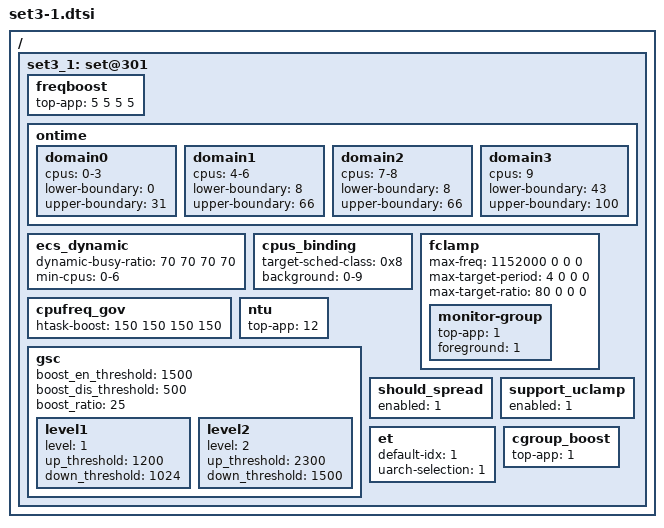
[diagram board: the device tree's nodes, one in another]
/ {
	/* game mode - boost app*/
	set3_1: set@301{
		/* Boosting margin applied to frequency selection */
		freqboost {			/* LIT MED-L MED-H BIG */
			top-app			= < 5  5  5  5 >;
		};

		/* Ontime Migration */
		ontime {
			domain0 {
				cpus = "0-3";
				lower-boundary = <0>;
				upper-boundary = <31>;
			};
			domain1 {
				cpus = "4-6";
				lower-boundary = <8>;
				upper-boundary = <66>;
			};
			domain2 {
				cpus = "7-8";
				lower-boundary = <8>;
				upper-boundary = <66>;
			};
			domain3 {
				cpus = "9";
				lower-boundary = <43>;
				upper-boundary = <100>;
			};
		};

		ecs_dynamic {
			dynamic-busy-ratio = <70 70 70 70>;
			min-cpus = "0-6";
		};

		/* cpus_binding applied to core selection */
		cpus_binding {
			target-sched-class = <0x8>;	/* fair */

			background	= "0-9";
		};

		fclamp {
			max-freq          = < 1152000       0       0       0>;
			max-target-period = <       4       0       0       0>;
			max-target-ratio  = <      80       0       0       0>;

			monitor-group {
				top-app         = <1>;
				foreground      = <1>;
			};
		};

		cpufreq_gov {
				/* LIT MED-L MED-H BIG */
			htask-boost = < 150 150 150 150 >;
		};

		ntu {
			top-app			= <12>;
		};
		
		gsc {
			boost_en_threshold = <1500>;
			boost_dis_threshold = <500>;
			boost_ratio = <25>;

			level1 {
				level = <1>;
				up_threshold = <1200>;
				down_threshold = <1024>;
			};
			level2 {
				level = <2>;
				up_threshold = <2300>;
				down_threshold = <1500>;
			};
		};
		
		should_spread {
			enabled = <1>;
		};

		support_uclamp {
			enabled = <1>;
		};

		et {
			default-idx = < 1 >;
			uarch-selection = < 1 >;
		};

		cgroup_boost {
			top-app = <1>;
		};

	};
};
